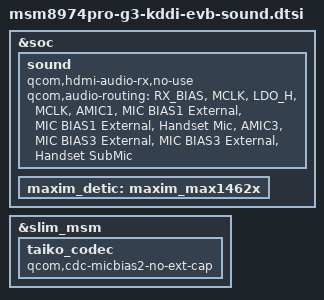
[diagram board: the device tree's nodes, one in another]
/* Copyright (c) 2013, LGE Electronics. All rights reserved.
 *
 * This program is free software; you can redistribute it and/or modify
 * it under the terms of the GNU General Public License version 2 and
 * only version 2 as published by the Free Software Foundation.
 *
 * This program is distributed in the hope that it will be useful,
 * but WITHOUT ANY WARRANTY; without even the implied warranty of
 * MERCHANTABILITY or FITNESS FOR A PARTICULAR PURPOSE.  See the
 * GNU General Public License for more details.
 */

&soc {

	sound {
		/* [AUDIO_BSP][tahiti] gooyeon.jung@lge.com 2014-02-04 disable HDMI by default */
		qcom,hdmi-audio-rx,no-use;

		/* [AUDIO_BSP][tahiti] gooyeon.jung@lge.com 2013-12-16 reset audio routing only for tahiti */
		qcom,audio-routing =
			"RX_BIAS", "MCLK",
			"LDO_H", "MCLK",
			"AMIC1", "MIC BIAS1 External",
			"MIC BIAS1 External", "Handset Mic",
			"AMIC3", "MIC BIAS3 External",
			"MIC BIAS3 External", "Handset SubMic";
	};

	maxim_detic:maxim_max1462x{
		status = "ok";
	};

};

&slim_msm {
	taiko_codec {
		qcom,cdc-micbias2-no-ext-cap;
	};
};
